# iostm32f205zx register map
Registers are 32-bit, access not given, no defined reset value unless marked. A register's access mark holds for its fields unless they carry their own. Addresses are absolute; registers are grouped by the start of their names; [hi:lo] are bit positions; {n}, {i} and the like mark numbered series.

## CAN
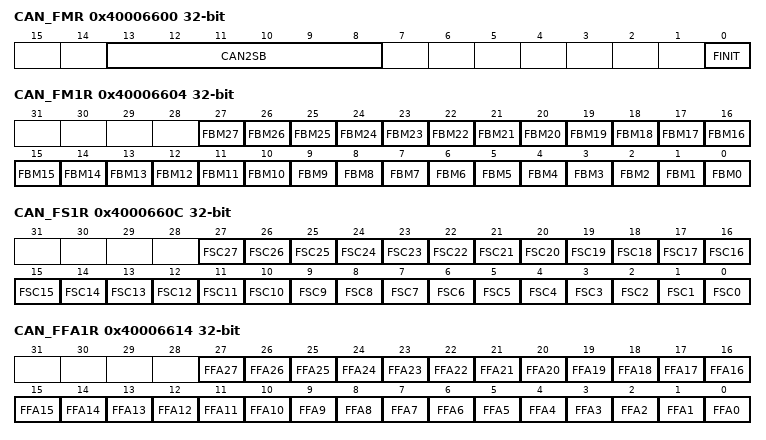
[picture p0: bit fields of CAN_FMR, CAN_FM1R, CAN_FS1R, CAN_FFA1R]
0x40006600 CAN_FMR
  [13:8] CAN2SB, [0] FINIT
0x40006604 CAN_FM1R
  [n] FBM{n} (n=0..27)
0x4000660C CAN_FS1R
  [n] FSC{n} (n=0..27)
0x40006614 CAN_FFA1R
  [n] FFA{n} (n=0..27)
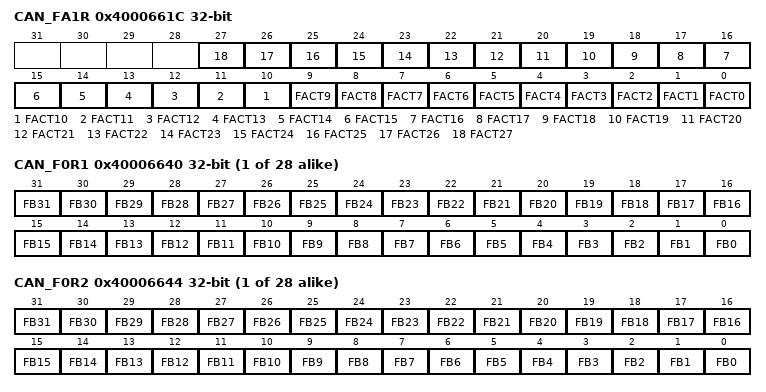
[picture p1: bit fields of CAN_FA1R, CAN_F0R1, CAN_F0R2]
0x4000661C CAN_FA1R
  [n] FACT{n} (n=0..27)
{0x40006640+8i} CAN_F{i}R1 (i=0..27)
  [n] FB{n} (n=0..31)
{0x40006644+8i} CAN_F{i}R2 (i=0..27)
  [n] FB{n} (n=0..31)

## I2C1
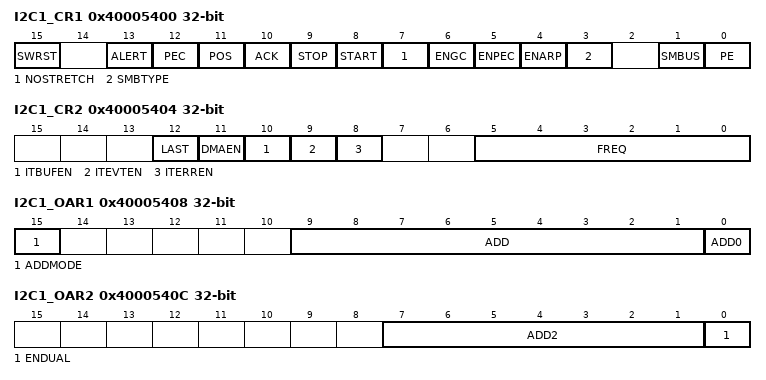
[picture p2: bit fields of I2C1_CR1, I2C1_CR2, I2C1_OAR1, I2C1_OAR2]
0x40005400 I2C1_CR1
  [15] SWRST, [13] ALERT, [12] PEC, [11] POS, [10] ACK, [9] STOP, [8] START, [7] NOSTRETCH, [6] ENGC, [5] ENPEC, [4] ENARP, [3] SMBTYPE, [1] SMBUS, [0] PE
0x40005404 I2C1_CR2
  [12] LAST, [11] DMAEN, [10] ITBUFEN, [9] ITEVTEN, [8] ITERREN, [5:0] FREQ
0x40005408 I2C1_OAR1
  [15] ADDMODE, [9:1] ADD, [0] ADD0
0x4000540C I2C1_OAR2
  [7:1] ADD2, [0] ENDUAL
0x40005410 I2C1_DR
  [7:0] DR
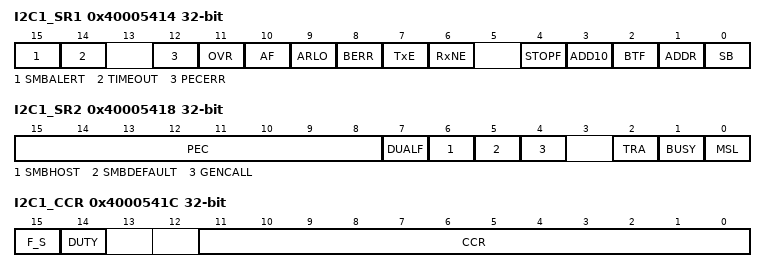
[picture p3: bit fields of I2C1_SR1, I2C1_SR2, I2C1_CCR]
0x40005414 I2C1_SR1
  [15] SMBALERT, [14] TIMEOUT, [12] PECERR, [11] OVR, [10] AF, [9] ARLO, [8] BERR, [7] TxE, [6] RxNE, [4] STOPF, [3] ADD10, [2] BTF, [1] ADDR, [0] SB
0x40005418 I2C1_SR2
  [15:8] PEC, [7] DUALF, [6] SMBHOST, [5] SMBDEFAULT, [4] GENCALL, [2] TRA, [1] BUSY, [0] MSL
0x4000541C I2C1_CCR
  [15] F_S, [14] DUTY, [11:0] CCR
0x40005420 I2C1_TRISE
  [5:0] TRISE

## I2C2
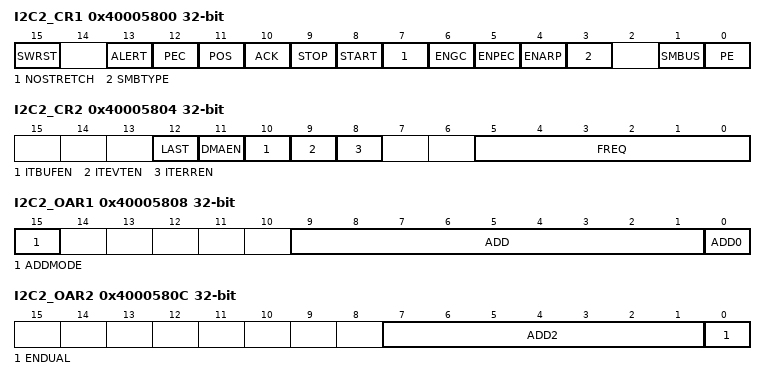
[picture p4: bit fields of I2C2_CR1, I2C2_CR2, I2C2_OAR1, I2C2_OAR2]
0x40005800 I2C2_CR1
  [15] SWRST, [13] ALERT, [12] PEC, [11] POS, [10] ACK, [9] STOP, [8] START, [7] NOSTRETCH, [6] ENGC, [5] ENPEC, [4] ENARP, [3] SMBTYPE, [1] SMBUS, [0] PE
0x40005804 I2C2_CR2
  [12] LAST, [11] DMAEN, [10] ITBUFEN, [9] ITEVTEN, [8] ITERREN, [5:0] FREQ
0x40005808 I2C2_OAR1
  [15] ADDMODE, [9:1] ADD, [0] ADD0
0x4000580C I2C2_OAR2
  [7:1] ADD2, [0] ENDUAL
0x40005810 I2C2_DR
  [7:0] DR
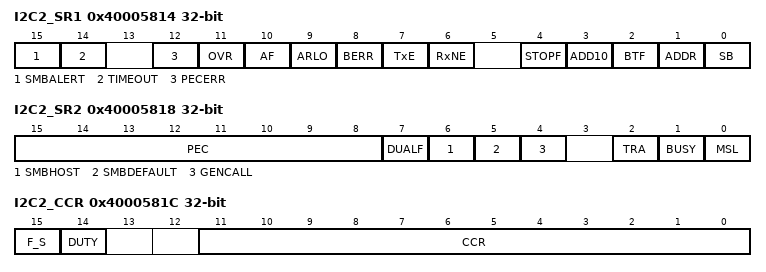
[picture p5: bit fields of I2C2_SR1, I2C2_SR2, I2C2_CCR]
0x40005814 I2C2_SR1
  [15] SMBALERT, [14] TIMEOUT, [12] PECERR, [11] OVR, [10] AF, [9] ARLO, [8] BERR, [7] TxE, [6] RxNE, [4] STOPF, [3] ADD10, [2] BTF, [1] ADDR, [0] SB
0x40005818 I2C2_SR2
  [15:8] PEC, [7] DUALF, [6] SMBHOST, [5] SMBDEFAULT, [4] GENCALL, [2] TRA, [1] BUSY, [0] MSL
0x4000581C I2C2_CCR
  [15] F_S, [14] DUTY, [11:0] CCR
0x40005820 I2C2_TRISE
  [5:0] TRISE

## I2C3
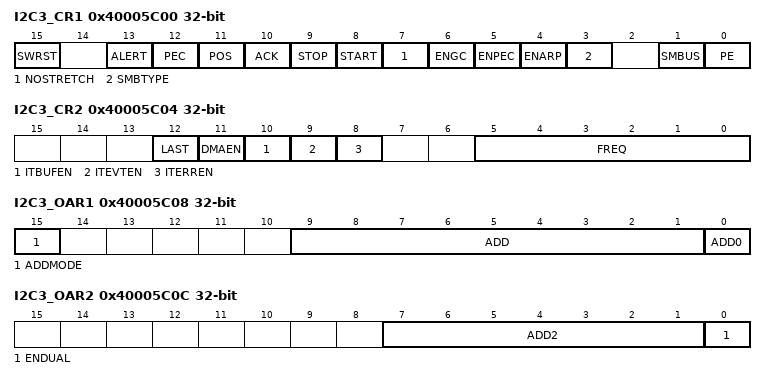
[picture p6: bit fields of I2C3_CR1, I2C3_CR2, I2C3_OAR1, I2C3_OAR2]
0x40005C00 I2C3_CR1
  [15] SWRST, [13] ALERT, [12] PEC, [11] POS, [10] ACK, [9] STOP, [8] START, [7] NOSTRETCH, [6] ENGC, [5] ENPEC, [4] ENARP, [3] SMBTYPE, [1] SMBUS, [0] PE
0x40005C04 I2C3_CR2
  [12] LAST, [11] DMAEN, [10] ITBUFEN, [9] ITEVTEN, [8] ITERREN, [5:0] FREQ
0x40005C08 I2C3_OAR1
  [15] ADDMODE, [9:1] ADD, [0] ADD0
0x40005C0C I2C3_OAR2
  [7:1] ADD2, [0] ENDUAL
0x40005C10 I2C3_DR
  [7:0] DR
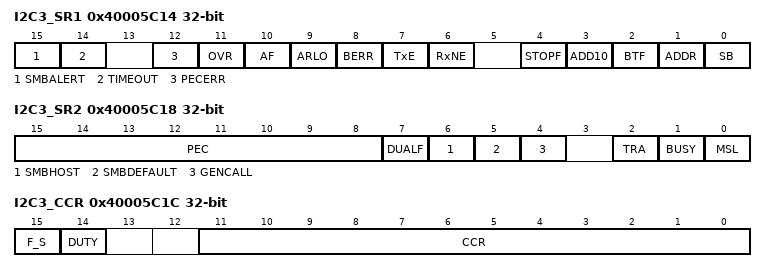
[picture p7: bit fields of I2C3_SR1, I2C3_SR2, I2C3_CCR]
0x40005C14 I2C3_SR1
  [15] SMBALERT, [14] TIMEOUT, [12] PECERR, [11] OVR, [10] AF, [9] ARLO, [8] BERR, [7] TxE, [6] RxNE, [4] STOPF, [3] ADD10, [2] BTF, [1] ADDR, [0] SB
0x40005C18 I2C3_SR2
  [15:8] PEC, [7] DUALF, [6] SMBHOST, [5] SMBDEFAULT, [4] GENCALL, [2] TRA, [1] BUSY, [0] MSL
0x40005C1C I2C3_CCR
  [15] F_S, [14] DUTY, [11:0] CCR
0x40005C20 I2C3_TRISE
  [5:0] TRISE

## SPI1
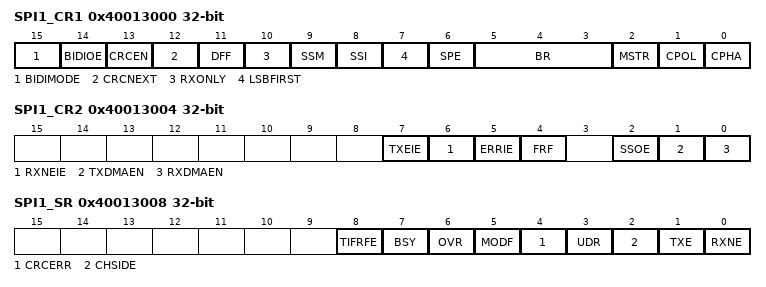
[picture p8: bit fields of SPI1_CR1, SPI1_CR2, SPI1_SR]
0x40013000 SPI1_CR1
  [15] BIDIMODE, [14] BIDIOE, [13] CRCEN, [12] CRCNEXT, [11] DFF, [10] RXONLY, [9] SSM, [8] SSI, [7] LSBFIRST, [6] SPE, [5:3] BR, [2] MSTR, [1] CPOL, [0] CPHA
0x40013004 SPI1_CR2
  [7] TXEIE, [6] RXNEIE, [5] ERRIE, [4] FRF, [2] SSOE, [1] TXDMAEN, [0] RXDMAEN
0x40013008 SPI1_SR
  [8] TIFRFE, [7] BSY, [6] OVR, [5] MODF, [4] CRCERR, [3] UDR, [2] CHSIDE, [1] TXE, [0] RXNE
0x4001300C SPI1_DR
  [15:0] DR
0x40013010 SPI1_CRCPR
  [15:0] CRCPOLY
0x40013014 SPI1_RXCRCR
  [15:0] RxCRC
0x40013018 SPI1_TXCRCR
  [15:0] TxCRC

## SPI2
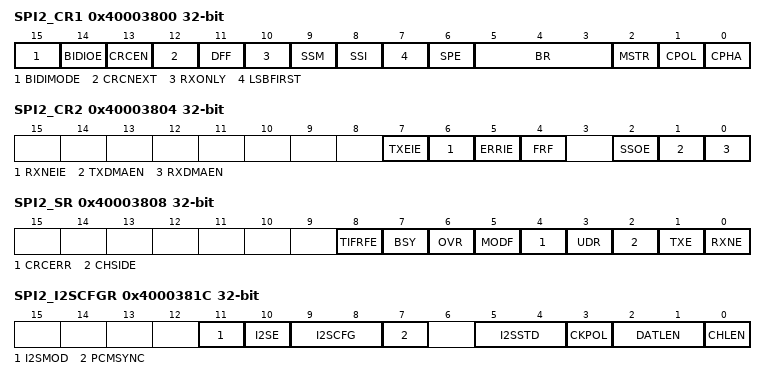
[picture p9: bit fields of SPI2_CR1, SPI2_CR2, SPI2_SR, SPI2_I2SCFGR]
0x40003800 SPI2_CR1
  [15] BIDIMODE, [14] BIDIOE, [13] CRCEN, [12] CRCNEXT, [11] DFF, [10] RXONLY, [9] SSM, [8] SSI, [7] LSBFIRST, [6] SPE, [5:3] BR, [2] MSTR, [1] CPOL, [0] CPHA
0x40003804 SPI2_CR2
  [7] TXEIE, [6] RXNEIE, [5] ERRIE, [4] FRF, [2] SSOE, [1] TXDMAEN, [0] RXDMAEN
0x40003808 SPI2_SR
  [8] TIFRFE, [7] BSY, [6] OVR, [5] MODF, [4] CRCERR, [3] UDR, [2] CHSIDE, [1] TXE, [0] RXNE
0x4000380C SPI2_DR
  [15:0] DR
0x40003810 SPI2_CRCPR
  [15:0] CRCPOLY
0x40003814 SPI2_RXCRCR
  [15:0] RxCRC
0x40003818 SPI2_TXCRCR
  [15:0] TxCRC
0x4000381C SPI2_I2SCFGR
  [11] I2SMOD, [10] I2SE, [9:8] I2SCFG, [7] PCMSYNC, [5:4] I2SSTD, [3] CKPOL, [2:1] DATLEN, [0] CHLEN
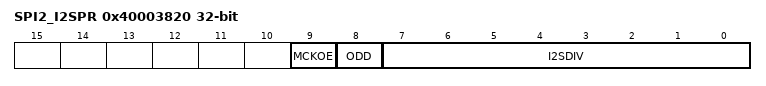
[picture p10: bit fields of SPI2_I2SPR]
0x40003820 SPI2_I2SPR
  [9] MCKOE, [8] ODD, [7:0] I2SDIV
